# AT32WB415 register map
Vendor: Keil; Series: AT32WB415; File version: 1.0
CPU: CM4 r0p1, little endian, no MPU, FPU, 4 interrupt priority bits
Registers are 32-bit, read-write, reset 0x0 unless marked. A register's access mark holds for its fields unless they carry their own. Offsets are from the block's base; [hi:lo] are bit positions; {n}, {i} and the like mark numbered series; 'fields as' and 'values as' point back to an identical list.

## DEBUG — Debug support
Base 0xE0042000
0x00 IDCODE ro — DEBUG IDCODE
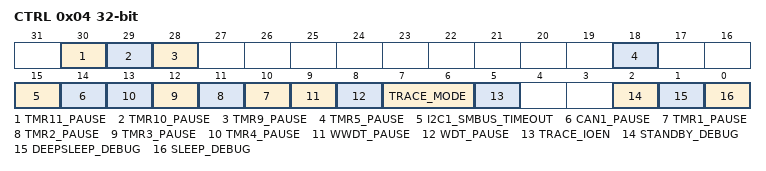
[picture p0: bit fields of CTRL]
0x04 CTRL — MCUDBG_CTRL
  [30] TMR11_PAUSE — Timer pause control bit
    0=Continue (The counter clock of TMRx is fed even if the core is halted); 1=Pause (The counter clock of TMRx is stopped when the core is halted)
  [29] TMR10_PAUSE — Timer pause control bit
    values as TMR11_PAUSE
  [28] TMR9_PAUSE — Timer pause control bit
    values as TMR11_PAUSE
  [18] TMR5_PAUSE — Timer pause control bit
    values as TMR11_PAUSE
  [15] I2C1_SMBUS_TIMEOUT
  [14] CAN1_PAUSE
  [n+9] TMR{n}_PAUSE (n=1..4) — Timer pause control bit
    values as TMR11_PAUSE
  [9] WWDT_PAUSE
    values as TMR11_PAUSE
  [8] WDT_PAUSE
    values as TMR11_PAUSE
  [7:6] TRACE_MODE
  [5] TRACE_IOEN
  [2] STANDBY_DEBUG — Debug Standby mode control bit
    on read: 0=Disabled (The whole 1.2V digital circuit is unpowered in Standby mode); 1=Enabled (The whole 1.2V digital circuit is not unpowered in Standby mode, and the system clock is provided by the internal RC oscillator (HICK)) | on write: 0=Disable (The whole 1.2V digital circuit is unpowered in Standby mode); 1=Enable (The whole 1.2V digital circuit is not unpowered in Standby mode, and the system clock is provided by the internal RC oscillator (HICK))
  [1] DEEPSLEEP_DEBUG — Debug Deepsleep mode control bit
    on read: 0=Disabled (In Deepsleep mode, all clocks in the 1.2V domain are disabled); 1=Enabled (In Deepsleep mode, system clock is provided by the internal RC oscillator (HICK)) | on write: 0=Disable (In Deepsleep mode, all clocks in the 1.2V domain are disabled); 1=Enable (In Deepsleep mode, system clock is provided by the internal RC oscillator (HICK))
  [0] SLEEP_DEBUG — Debug Sleep mode control bit
    on read: 0=Disabled (When entering Sleep mode, CPU HCLK clock is disabled, but other clocks remain active); 1=Enabled (When entering Sleep mode, all clocks keep running) | on write: 0=Disable (When entering Sleep mode, CPU HCLK clock is disabled, but other clocks remain active); 1=Enable (When entering Sleep mode, all clocks keep running)

## CRC — CRC calculation unit
Base 0x40023000
0x00 DT reset 0xFFFFFFFF — Data register
0x04 CDT — Common data register
  [7:0] CDT — Common Data
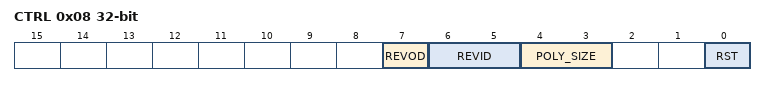
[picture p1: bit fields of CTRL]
0x08 CTRL — Control register
  [7] REVOD ro — Reverse output data
    0=NoEffect; 1=WordReverse
  [6:5] REVID — Reverse input data
    0=NoEffect; 1=ByteReverse; 2=HalfWordReverse; 3=WordReverse
  [4:3] POLY_SIZE — Polynomial size
    0=bits32 (32 bits); 1=bits16 (16 bits); 2=bits8 (8 bits); 3=bits7 (7 bits)
  [0] RST write-1-sets — Reset bit
    on write: 1=Reset CRC calculation unit, the data register is set as 0xFFFF FFFF
0x10 IDT reset 0xFFFFFFFF — Initial data register
0x14 POLY reset 0x4C11DB7 — Polynomial coefficient register

## FLASH — Flash memory controler
Base 0x40022000
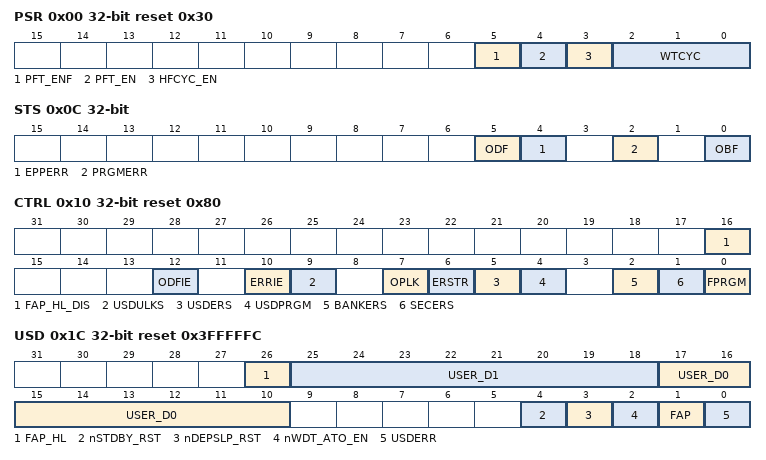
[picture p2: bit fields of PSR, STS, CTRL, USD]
0x00 PSR reset 0x30 — Performance selection register
  [5] PFT_ENF ro — Prefetch enabled flag
  [4] PFT_EN — Prefetch enable
  [3] HFCYC_EN — Half cycle acceleration access enable
  [2:0] WTCYC — Wait cycle
0x04 UNLOCK wo
  [31:0] UKVAL — Unlock key value
0x08 USD_UNLOCK wo
  [31:0] USD_UKVAL — User system data Unlock key value
0x0C STS — Status register
  [5] ODF — Operate done flag
  [4] EPPERR — Erase/program protection error
  [2] PRGMERR — program error
  [0] OBF ro — Operate busy flag
0x10 CTRL reset 0x80 — Control register
  [16] FAP_HL_DIS — FAP high level disable
  [12] ODFIE — Operation done flag interrupt enable
  [10] ERRIE — Error interrupt enable
  [9] USDULKS — User system data unlock success
  [7] OPLK — Operation lock
  [6] ERSTR — Erasing start
  [5] USDERS — User system data erase
  [4] USDPRGM — User system data program
  [2] BANKERS — Bank erase
  [1] SECERS — Sector erase
  [0] FPRGM — Flash program
0x14 ADDR wo — Address register
  [31:0] FA — Flash Address
0x1C USD ro reset 0x3FFFFFC — User system data register
  [26] FAP_HL — FAP high level
  [25:18] USER_D1 — User data 1
  [17:10] USER_D0 — User data 0
  [4] nSTDBY_RST — Standby reset
  [3] nDEPSLP_RST — Deepsleep reset
  [2] nWDT_ATO_EN — WDT auto enable
  [1] FAP — FLASH access protection
  [0] USDERR — User system data error
0x20 EPPS ro reset 0xFFFFFFFF — Erase/program protection status register
  [31:0] EPPS — Erase/program protection status
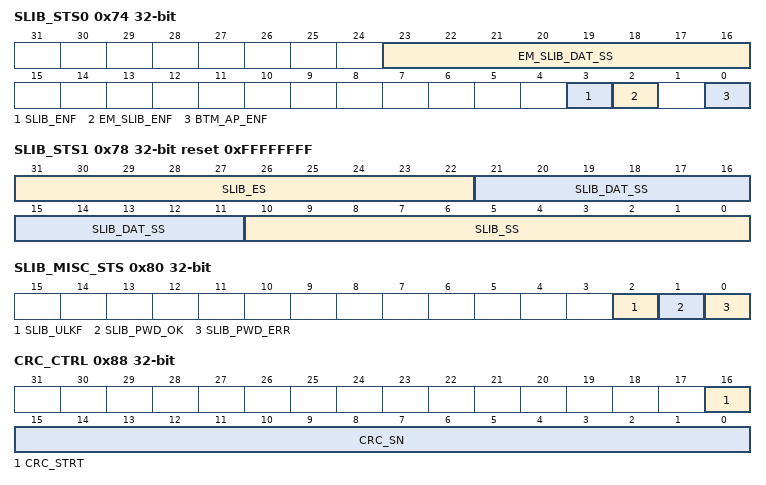
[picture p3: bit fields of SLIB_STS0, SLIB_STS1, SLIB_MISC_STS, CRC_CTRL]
0x74 SLIB_STS0 ro — sLib status 0 register
  [23:16] EM_SLIB_DAT_SS — Extension memory sLib data start sector
  [3] SLIB_ENF — sLib enabled flag
  [2] EM_SLIB_ENF — Extension memory sLib enabled flag
  [0] BTM_AP_ENF — Boot memory store application code enabled flag
0x78 SLIB_STS1 ro reset 0xFFFFFFFF — sLib status 1 register
  [31:22] SLIB_ES — sLib end sector
  [21:11] SLIB_DAT_SS — sLib data start sector
  [10:0] SLIB_SS — sLib start sector
0x7C SLIB_PWD_CLR wo — SLIB password clear register
  [31:0] SLIB_PCLR_VAL — sLib password clear value
0x80 SLIB_MISC_STS — sLib misc status register
  [2] SLIB_ULKF ro — sLib unlock flag
  [1] SLIB_PWD_OK ro — sLib password ok
  [0] SLIB_PWD_ERR ro — sLib password error
0x84 CRC_ADDR wo — Flash CRC data start address register
  [31:0] CRC_ADDR — CRC address
0x88 CRC_CTRL — Flash CRC controll register
  [16] CRC_STRT wo — CRC start
  [15:0] CRC_SN — CRC sector numbler
0x8C CRC_CHKR ro — FLASH CRC check result register
  [31:0] FCRC_OUT — CRC32 verification result of flash user code or SLIB code
0x160 SLIB_SET_PWD wo — sLib password setting register
  [31:0] SLIB_PSET_VAL — sLib password setting val
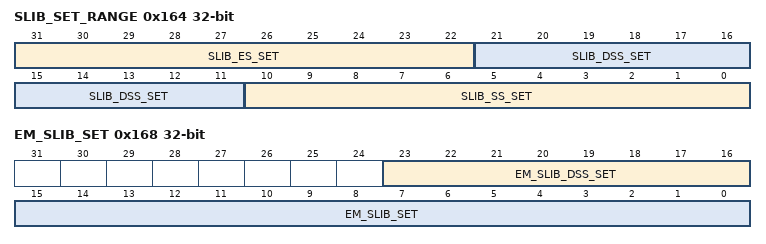
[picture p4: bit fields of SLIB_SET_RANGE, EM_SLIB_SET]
0x164 SLIB_SET_RANGE wo — Configure sLib range register
  [31:22] SLIB_ES_SET — sLib end sector setting
  [21:11] SLIB_DSS_SET — sLib data start sector setting
  [10:0] SLIB_SS_SET — sLib start sector setting
0x168 EM_SLIB_SET wo — Extension momery slib set register
  [23:16] EM_SLIB_DSS_SET — Extension memory sLib data start sector setting
  [15:0] EM_SLIB_SET — Extension memory sLib setting
0x16C BTM_MODE_SET wo — Boot memory mode setting register
  [7:0] BTM_MODE_SET — Boot memory mode setting
0x170 SLIB_UNLOCK wo
  [31:0] SLIB_UKVAL — sLib unlock key value
